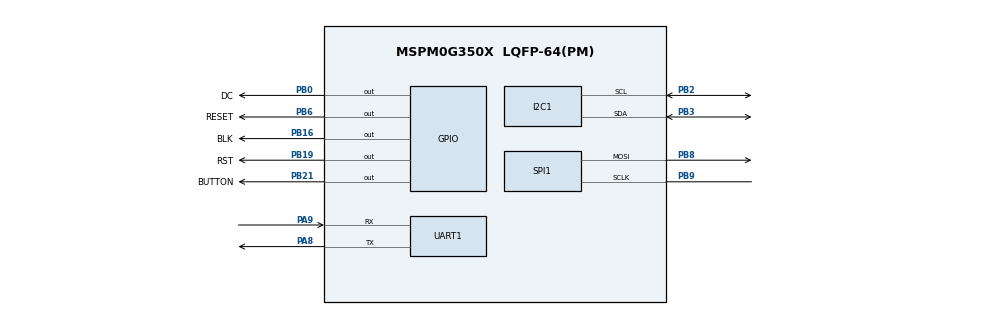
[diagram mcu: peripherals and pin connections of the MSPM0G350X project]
/**
 * @cliArgs --device "MSPM0G350X" --part "Default" --package "LQFP-64(PM)" --product "mspm0_sdk@2.10.00.04"
 * @versions {"tool":"1.27.0+4565"}
 */

/**
 * Import the modules used in this configuration.
 */
const GPIO          = scripting.addModule("/ti/driverlib/GPIO", {}, false);
const GPIO1         = GPIO.addInstance();
const GPIO2         = GPIO.addInstance();
const GPIO3         = GPIO.addInstance();
const I2C           = scripting.addModule("/ti/driverlib/I2C", {}, false);
const I2C1          = I2C.addInstance();
const SPI           = scripting.addModule("/ti/driverlib/SPI", {}, false);
const SPI1          = SPI.addInstance();
const SYSCTL        = scripting.addModule("/ti/driverlib/SYSCTL");
const UART          = scripting.addModule("/ti/driverlib/UART", {}, false);
const UART1         = UART.addInstance();
const WWDT          = scripting.addModule("/ti/driverlib/WWDT", {}, false);
const WWDT1         = WWDT.addInstance();
const ProjectConfig = scripting.addModule("/ti/project_config/ProjectConfig");

/**
 * Write custom configuration values to the imported modules.
 */
GPIO1.$name                         = "ST7789";
GPIO1.associatedPins.create(3);
GPIO1.associatedPins[0].$name       = "DC";
GPIO1.associatedPins[0].pin.$assign = "PB0";
GPIO1.associatedPins[1].$name       = "RESET";
GPIO1.associatedPins[1].pin.$assign = "PB6";
GPIO1.associatedPins[2].$name       = "BLK";
GPIO1.associatedPins[2].pin.$assign = "PB16";

const Board = scripting.addModule("/ti/driverlib/Board", {}, false);

GPIO2.$name                               = "JOY";
GPIO2.associatedPins[0].$name             = "BUTTON";
GPIO2.associatedPins[0].launchPadShortcut = "Button3En";
GPIO2.associatedPins[0].interruptEn       = true;
GPIO2.associatedPins[0].polarity          = "FALL";
GPIO2.associatedPins[0].pin.$assign       = "PB21";

GPIO3.$name                         = "ESP8266";
GPIO3.associatedPins[0].$name       = "RST";
GPIO3.associatedPins[0].pin.$assign = "PB19";

I2C1.$name                             = "I2C";
I2C1.basicEnableController             = true;
I2C1.peripheral.$assign                = "I2C1";
I2C1.peripheral.sdaPin.$assign         = "PB3";
I2C1.peripheral.sclPin.$assign         = "PB2";
I2C1.sdaPinConfig.$name                = "ti_driverlib_gpio_GPIOPinGeneric0";
I2C1.sdaPinConfig.hideOutputInversion  = scripting.forceWrite(false);
I2C1.sdaPinConfig.onlyInternalResistor = scripting.forceWrite(false);
I2C1.sdaPinConfig.passedPeripheralType = scripting.forceWrite("Digital");
I2C1.sclPinConfig.$name                = "ti_driverlib_gpio_GPIOPinGeneric1";
I2C1.sclPinConfig.hideOutputInversion  = scripting.forceWrite(false);
I2C1.sclPinConfig.onlyInternalResistor = scripting.forceWrite(false);
I2C1.sclPinConfig.passedPeripheralType = scripting.forceWrite("Digital");

SPI1.$name                              = "SPI";
SPI1.polarity                           = "1";
SPI1.phase                              = "1";
SPI1.peripheral.$assign                 = "SPI1";
SPI1.peripheral.sclkPin.$assign         = "PB9";
SPI1.peripheral.mosiPin.$assign         = "PB8";
SPI1.sclkPinConfig.$name                = "ti_driverlib_gpio_GPIOPinGeneric2";
SPI1.sclkPinConfig.direction            = scripting.forceWrite("OUTPUT");
SPI1.sclkPinConfig.onlyInternalResistor = scripting.forceWrite(false);
SPI1.sclkPinConfig.passedPeripheralType = scripting.forceWrite("Digital");
SPI1.mosiPinConfig.$name                = "ti_driverlib_gpio_GPIOPinGeneric3";
SPI1.mosiPinConfig.direction            = scripting.forceWrite("OUTPUT");
SPI1.mosiPinConfig.hideOutputInversion  = scripting.forceWrite(false);
SPI1.mosiPinConfig.onlyInternalResistor = scripting.forceWrite(false);
SPI1.mosiPinConfig.passedPeripheralType = scripting.forceWrite("Digital");
SPI1.misoPinConfig.$name                = "ti_driverlib_gpio_GPIOPinGeneric4";
SPI1.misoPinConfig.onlyInternalResistor = scripting.forceWrite(false);
SPI1.misoPinConfig.passedPeripheralType = scripting.forceWrite("Digital");
SPI1.cs0PinConfig.$name                 = "ti_driverlib_gpio_GPIOPinGeneric5";
SPI1.cs0PinConfig.direction             = scripting.forceWrite("OUTPUT");
SPI1.cs0PinConfig.hideOutputInversion   = scripting.forceWrite(false);
SPI1.cs0PinConfig.onlyInternalResistor  = scripting.forceWrite(false);
SPI1.cs0PinConfig.passedPeripheralType  = scripting.forceWrite("Digital");

SYSCTL.clockTreeEn = true;

UART1.$name                            = "UART";
UART1.peripheral.$assign               = "UART1";
UART1.peripheral.rxPin.$assign         = "PA9";
UART1.peripheral.txPin.$assign         = "PA8";
UART1.txPinConfig.$name                = "ti_driverlib_gpio_GPIOPinGeneric6";
UART1.txPinConfig.direction            = scripting.forceWrite("OUTPUT");
UART1.txPinConfig.hideOutputInversion  = scripting.forceWrite(false);
UART1.txPinConfig.onlyInternalResistor = scripting.forceWrite(false);
UART1.txPinConfig.passedPeripheralType = scripting.forceWrite("Digital");
UART1.rxPinConfig.$name                = "ti_driverlib_gpio_GPIOPinGeneric7";
UART1.rxPinConfig.hideOutputInversion  = scripting.forceWrite(false);
UART1.rxPinConfig.onlyInternalResistor = scripting.forceWrite(false);
UART1.rxPinConfig.passedPeripheralType = scripting.forceWrite("Digital");

WWDT1.$name       = "WDT";
WWDT1.periodCount = "15";

ProjectConfig.genDisable = true;

/**
 * Pinmux solution for unlocked pins/peripherals. This ensures that minor changes to the automatic solver in a future
 * version of the tool will not impact the pinmux you originally saw.  These lines can be completely deleted in order to
 * re-solve from scratch.
 */
Board.peripheral.$suggestSolution          = "DEBUGSS";
Board.peripheral.swclkPin.$suggestSolution = "PA20";
Board.peripheral.swdioPin.$suggestSolution = "PA19";
SPI1.peripheral.misoPin.$suggestSolution   = "PA16";
SPI1.peripheral.cs0Pin.$suggestSolution    = "PA2";
WWDT1.peripheral.$suggestSolution          = "WWDT0";
